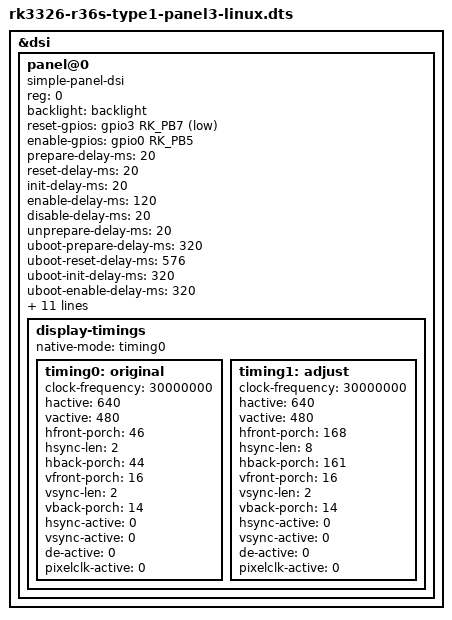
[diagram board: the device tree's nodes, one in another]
// SPDX-License-Identifier: (GPL-2.0+ OR MIT)
/*
* Copyright (c) 2025 kk&lcdyk
*
* R36S Clone掌机 种类1
*
*/

/dts-v1/;
#include "rk3326-r36s-type1-panel1-linux.dts"

&dsi {
	status = "okay";
	
	panel@0 {
		compatible = "simple-panel-dsi";
		reg = <0>;
		/* pwm1 backlight */
		backlight = <&backlight>;
		/* LCD reset gpio GPIO3.B7 */
		reset-gpios = <&gpio3 RK_PB7 GPIO_ACTIVE_LOW>;
		/* LCD reset gpio GPIO0.B5 */
		enable-gpios = <&gpio0 RK_PB5 GPIO_ACTIVE_HIGH>;
		prepare-delay-ms = <20>;
		reset-delay-ms = <20>;
		init-delay-ms = <20>;
		enable-delay-ms = <120>;
		disable-delay-ms = <20>;
		unprepare-delay-ms = <20>;
		uboot-prepare-delay-ms = <320>;
		uboot-reset-delay-ms = <576>;
		uboot-init-delay-ms = <320>;
		uboot-enable-delay-ms = <320>;
		uboot-disable-delay-ms = <320>;
		uboot-unprepare-delay-ms = <20>;
		width-mm = <153>;
		height-mm = <85>;
		dsi,flags  = <(MIPI_DSI_MODE_VIDEO |
		MIPI_DSI_MODE_VIDEO_BURST |
		MIPI_DSI_MODE_LPM |
		MIPI_DSI_MODE_EOT_PACKET)>;
		dsi,format = <MIPI_DSI_FMT_RGB888>;
		dsi,lanes = <4>;
		panel-init-sequence = [15 00 02 ff 30 15 00 02 ff 52 15 00 02 ff 01 15 00 02 e3 00 15 00 02 25 10 15 00 02 28 6f 15 00 02 29 01 15 00 02 2a df 15 00 02 2c 26 15 00 02 30 58 15 00 02 37 9c 15 00 02 38 a7 15 00 02 39 53 15 00 02 44 00 15 00 02 49 3c 15 00 02 59 fe 15 00 02 5c 00 15 00 02 60 8f 15 00 02 80 20 15 00 02 91 77 15 00 02 92 77 15 00 02 a0 55 15 00 02 a1 50 15 00 02 a3 58 15 00 02 a4 9c 15 00 02 a7 02 15 00 02 a8 01 15 00 02 a9 21 15 00 02 aa fc 15 00 02 ab 28 15 00 02 ac 06 15 00 02 ad 06 15 00 02 ae 06 15 00 02 af 03 15 00 02 b0 08 15 00 02 b1 26 15 00 02 b2 28 15 00 02 b3 28 15 00 02 b4 03 15 00 02 b5 08 15 00 02 b6 26 15 00 02 b7 08 15 00 02 b8 26 15 00 02 c0 00 15 00 02 c1 00 15 00 02 c2 00 15 00 02 c3 0f 15 00 02 ff 30 15 00 02 ff 52 15 00 02 ff 02 15 00 02 b0 0b 15 00 02 b1 16 15 00 02 b2 17 15 00 02 b3 2c 15 00 02 b4 32 15 00 02 b5 3b 15 00 02 b6 29 15 00 02 b7 40 15 00 02 b8 0d 15 00 02 b9 05 15 00 02 ba 12 15 00 02 bb 10 15 00 02 bc 12 15 00 02 bd 15 15 00 02 be 19 15 00 02 bf 0e 15 00 02 c0 16 15 00 02 c1 0a 15 00 02 d0 0c 15 00 02 d1 17 15 00 02 d2 14 15 00 02 d3 2e 15 00 02 d4 32 15 00 02 d5 3c 15 00 02 d6 22 15 00 02 d7 3d 15 00 02 d8 0d 15 00 02 d9 07 15 00 02 da 13 15 00 02 db 13 15 00 02 dc 11 15 00 02 dd 15 15 00 02 de 19 15 00 02 df 10 15 00 02 e0 17 15 00 02 e1 0a 15 00 02 ff 30 15 00 02 ff 52 15 00 02 ff 03 15 00 02 00 00 15 00 02 01 00 15 00 02 02 00 15 00 02 03 00 15 00 02 04 61 15 00 02 05 80 15 00 02 06 c7 15 00 02 07 01 15 00 02 08 82 15 00 02 09 83 15 00 02 30 00 15 00 02 31 00 15 00 02 32 00 15 00 02 33 00 15 00 02 34 61 15 00 02 35 c5 15 00 02 36 80 15 00 02 37 23 15 00 02 40 82 15 00 02 41 83 15 00 02 42 80 15 00 02 43 81 15 00 02 44 11 15 00 02 45 e2 15 00 02 46 e1 15 00 02 47 11 15 00 02 48 e4 15 00 02 49 e3 15 00 02 50 02 15 00 02 51 01 15 00 02 52 04 15 00 02 53 03 15 00 02 54 11 15 00 02 55 e6 15 00 02 56 e5 15 00 02 57 11 15 00 02 58 e8 15 00 02 59 e7 15 00 02 7e 08 15 00 02 81 0f 15 00 02 84 0c 15 00 02 85 0d 15 00 02 86 07 15 00 02 87 04 15 00 02 88 05 15 00 02 89 06 15 00 02 8a 00 15 00 02 97 0f 15 00 02 9a 0c 15 00 02 9b 0d 15 00 02 9c 07 15 00 02 9d 04 15 00 02 9e 05 15 00 02 9f 06 15 00 02 a0 00 15 00 02 e0 02 15 00 02 e1 52 15 00 02 ff 30 15 00 02 ff 52 15 00 02 ff 00 15 00 02 36 02 05 c8 01 11 05 64 01 29];
		panel-exit-sequence = <0x5000128 0x5000110>;
		
		display-timings {
			native-mode = <&timing0>;
			
			// 30.00MHz / (640+46+2+44)×(480+16+2+14) = 732×512 = 80.05 Hz
			timing0: original {
				clock-frequency = <30000000>;
				hactive = <640>;
				vactive = <480>;
				hfront-porch = <46>;
				hsync-len = <2>;
				hback-porch = <44>;
				vfront-porch = <16>;
				vsync-len = <2>;
				vback-porch = <14>;
				hsync-active = <0>;
				vsync-active = <0>;
				de-active = <0>;
				pixelclk-active = <0>;
			};
			
			// 30.00MHz / (640+168+8+161)×(480+16+2+14) = 977×512 = 59.97 Hz
			timing1: adjust {
				clock-frequency = <30000000>;
				hactive = <640>;
				vactive = <480>;
				hfront-porch = <168>;
				hsync-len = <8>;
				hback-porch = <161>;
				vfront-porch = <16>;
				vsync-len = <2>;
				vback-porch = <14>;
				hsync-active = <0>;
				vsync-active = <0>;
				de-active = <0>;
				pixelclk-active = <0>;
			};
		};
	};
};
